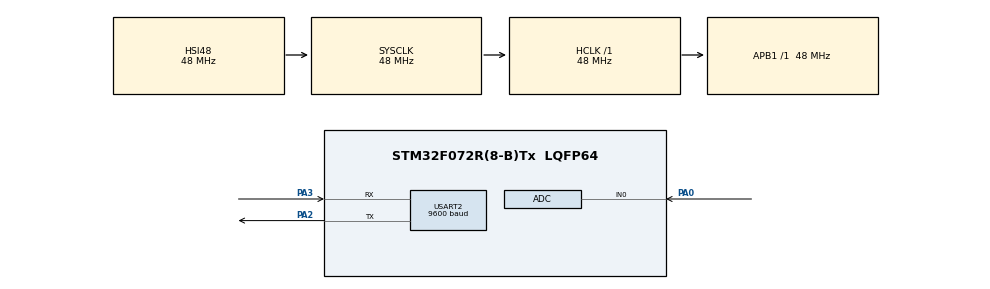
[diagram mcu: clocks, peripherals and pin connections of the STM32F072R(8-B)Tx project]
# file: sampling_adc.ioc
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ADC.ExternalTrigConv=ADC_EXTERNALTRIGCONV_T1_TRGO
Mcu.Family=STM32F0
Mcu.Name=STM32F072R(8-B)Tx
Mcu.Package=LQFP64
NVIC.ADC1_COMP_IRQn=true\:0\:0\:false\:false\:true\:true\:true
NVIC.TIM7_IRQn=true\:0\:0\:false\:false\:true\:true\:true
NVIC.USART2_IRQn=true\:0\:0\:false\:false\:true\:true\:true
PA0.Mode=IN0
PA0.Signal=ADC_IN0
PA2.Mode=Asynchronous
PA2.Signal=USART2_TX
PA3.Mode=Asynchronous
PA3.Signal=USART2_RX
ProjectManager.HeapSize=0x200
ProjectManager.StackSize=0x400
ProjectManager.TargetToolchain=MDK-ARM V5.27
RCC.AHBFreq_Value=48000000
RCC.APB1Freq_Value=48000000
RCC.APB1TimFreq_Value=48000000
RCC.HCLKFreq_Value=48000000
RCC.SYSCLKFreq_VALUE=48000000
RCC.SYSCLKSource=RCC_SYSCLKSOURCE_HSI48
TIM1.Period=48000
TIM1.TIM_MasterOutputTrigger=TIM_TRGO_ENABLE
TIM7.Period=48
TIM7.Prescaler=1
USART2.BaudRate=9600
USART2.VirtualMode-Asynchronous=VM_ASYNC
VP_ADC_Vref_Input.Mode=IN-Vrefint
VP_TIM1_VS_ClockSourceINT.Mode=Internal
VP_TIM7_VS_ClockSourceINT.Mode=Enable_Timer
board=custom

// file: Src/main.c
/* USER CODE BEGIN Header */
/**
  ******************************************************************************
  * @file           : main.c
  * @brief          : Main program body
  ******************************************************************************
  * @attention
  *
  * <h2><center>&copy; Copyright (c) 2019 STMicroelectronics.
  * All rights reserved.</center></h2>
  *
  * This software component is licensed by ST under BSD 3-Clause license,
  * the "License"; You may not use this file except in compliance with the
  * License. You may obtain a copy of the License at:
  *                        opensource.org/licenses/BSD-3-Clause
  *
  ******************************************************************************
  */
/* USER CODE END Header */

#include "main.h"

/* USER CODE BEGIN PTD */
#define size 100
int lenght_triggering=80;
int triggered=0;
int triggering=0;
int inizio=0;
int V_th=1000;
int values[size];
//float small_val[100]; //di questi verra fatto il valor medio, il quale verra inserito in values
int loops;
int i=0;//indice di values
int j=0;//indice di small_values
int ADC_CC=0; //adc conversion complete
uint32_t valore;
char msg[6];
int resto,m,m_1;
char * puntatore;
int lenght_da_trasmettere;
int vrefint_data;
int end=0;
int tmp1[100];
int tmp1_index,tmp2_index;
/* USER CODE END PTD */

ADC_HandleTypeDef hadc;

TIM_HandleTypeDef htim1;
TIM_HandleTypeDef htim7;

UART_HandleTypeDef huart2;

void SystemClock_Config(void);
static void MX_GPIO_Init(void);
static void MX_ADC_Init(void);
static void MX_USART2_UART_Init(void);
static void MX_TIM7_Init(void);
static void MX_TIM1_Init(void);

int main(void)
{
  /* USER CODE BEGIN 1 */
	int loops_2;
  /* USER CODE END 1 */

  /* MCU Configuration--------------------------------------------------------*/

  /* Reset of all peripherals, Initializes the Flash interface and the Systick. */
  HAL_Init();

  /* Configure the system clock */
  SystemClock_Config();

  /* Initialize all configured peripherals */
  MX_GPIO_Init();
  MX_ADC_Init();
  MX_USART2_UART_Init();
  MX_TIM7_Init();
  MX_TIM1_Init();
  /* USER CODE BEGIN 2 */
	ADC1->IER|=ADC_IER_ADRDYIE;
	ADC1->IER|=ADC_IER_EOCIE;

	//abilito e configuro l'adc
	//se fosse giа abilitato lo disabilito per fare la calibrazione
	if ((ADC1->CR & ADC_CR_ADEN) != 0)
	{
		ADC1->CR |= ADC_CR_ADDIS;
	}
	//aspetto che non sia piu enable
	while ((ADC1->CR & ADC_CR_ADEN) != 0){}
	//faccio la calibrazione
	ADC1->CR|=ADC_CR_ADCAL;
	//ed aspetto che abbia finito
	while((ADC1->CR & ADC_CR_ADCAL)==ADC_CR_ADCAL){}
	//se adrdy fosse 1 la metto a 0
	if ((ADC1->ISR & ADC_ISR_ADRDY) != 0)
	{
		ADC1->ISR |= ADC_ISR_ADRDY;
	}
	//abilito
	ADC1->CHSELR&=~ADC_CHSELR_CHSEL0;
	ADC1->CR|=ADC_CR_ADEN;
	ADC1->CR|=ADC_CR_ADSTART;
	TIM1->CR1|=TIM_CR1_CEN;
	//verra triggerato l'interrupt quando sarа pronto

	//adesso dovrebbe essere stato registrato il valore vrefint_data
	//aspetto 1 millisecondo

	//cambio il canale da cui leggere il dato nell'adc

	//faccio ripartire la lettura

	while(!ADC_CC){}
	//devo riordinare il buffer circolare

	if(inizio!=0){
		//riordino il buffer
		tmp1_index=inizio;
		while(tmp1_index!=lenght_triggering){
			tmp1[tmp1_index-inizio]=values[tmp1_index];
			tmp1_index++;
		}
		tmp2_index=0;
		while(tmp1_index!=lenght_triggering+inizio){
			tmp1[tmp1_index-inizio]=values[tmp2_index];
			tmp1_index++;
			tmp2_index++;
		}
		//copio in values
		tmp1_index=0;
		while(tmp1_index!=lenght_triggering){
			values[tmp1_index]=tmp1[tmp1_index];
			tmp1_index++;
		}
	}
	valore=*(uint16_t*)0x1FFFF7BA;
	m=valore;
	m_1=1000;
	msg[0]=(int)(m/m_1)+'0'; //m prima cifra
	resto=(m)%m_1;//resto
	msg[1]=(int)(resto*10/m_1)+'0';//m seconda cifra
	resto=(resto*10)%m_1;//resto
	msg[2]=(int)(resto*10/m_1)+'0';//m terza cifra
	resto=(resto*10)%m_1;
	msg[3]=(int)(resto*10/m_1)+'0';

	//trasmetto i dati con la usart2

	//reset del interrupt control register al bit trasmission completed
	USART2->ICR |= USART_ICR_TCCF;
	//abilito l'interrupt per la trasmissione
	USART2->CR1 |= USART_CR1_TCIE;
	//abilito l'interrupt per la ricezione
	USART2->CR1 |= USART_CR1_RXNEIE;
	//inizio a trasmettere il messaggio di benvenuto
	i=0;//indice msg
	j=-2;//indice values, aggiungo all'inizio valore e vrefint
	msg[4]=10;
	msg[5]=13;
	lenght_da_trasmettere=6;
	puntatore=msg;
	USART2->TDR=*puntatore;
  /* USER CODE END 2 */

  /* Infinite loop */
  while (1)
  {

  }
}

void SystemClock_Config(void)
{
  RCC_OscInitTypeDef RCC_OscInitStruct = {0};
  RCC_ClkInitTypeDef RCC_ClkInitStruct = {0};
  RCC_PeriphCLKInitTypeDef PeriphClkInit = {0};

  /** Initializes the CPU, AHB and APB busses clocks
  */
  RCC_OscInitStruct.OscillatorType = RCC_OSCILLATORTYPE_HSI14|RCC_OSCILLATORTYPE_HSI48;
  RCC_OscInitStruct.HSI48State = RCC_HSI48_ON;
  RCC_OscInitStruct.HSI14State = RCC_HSI14_ON;
  RCC_OscInitStruct.HSI14CalibrationValue = 16;
  RCC_OscInitStruct.PLL.PLLState = RCC_PLL_NONE;
  if (HAL_RCC_OscConfig(&RCC_OscInitStruct) != HAL_OK)
  {
    Error_Handler();
  }
  /** Initializes the CPU, AHB and APB busses clocks
  */
  RCC_ClkInitStruct.ClockType = RCC_CLOCKTYPE_HCLK|RCC_CLOCKTYPE_SYSCLK
                              |RCC_CLOCKTYPE_PCLK1;
  RCC_ClkInitStruct.SYSCLKSource = RCC_SYSCLKSOURCE_HSI48;
  RCC_ClkInitStruct.AHBCLKDivider = RCC_SYSCLK_DIV1;
  RCC_ClkInitStruct.APB1CLKDivider = RCC_HCLK_DIV1;

  if (HAL_RCC_ClockConfig(&RCC_ClkInitStruct, FLASH_LATENCY_1) != HAL_OK)
  {
    Error_Handler();
  }
  PeriphClkInit.PeriphClockSelection = RCC_PERIPHCLK_USART2;
  PeriphClkInit.Usart2ClockSelection = RCC_USART2CLKSOURCE_PCLK1;
  if (HAL_RCCEx_PeriphCLKConfig(&PeriphClkInit) != HAL_OK)
  {
    Error_Handler();
  }
}

static void MX_ADC_Init(void)
{

  ADC_ChannelConfTypeDef sConfig = {0};

  /** Configure the global features of the ADC (Clock, Resolution, Data Alignment and number of conversion)
  */
  hadc.Instance = ADC1;
  hadc.Init.ClockPrescaler = ADC_CLOCK_ASYNC_DIV1;
  hadc.Init.Resolution = ADC_RESOLUTION_12B;
  hadc.Init.DataAlign = ADC_DATAALIGN_RIGHT;
  hadc.Init.ScanConvMode = ADC_SCAN_DIRECTION_FORWARD;
  hadc.Init.EOCSelection = ADC_EOC_SINGLE_CONV;
  hadc.Init.LowPowerAutoWait = DISABLE;
  hadc.Init.LowPowerAutoPowerOff = DISABLE;
  hadc.Init.ContinuousConvMode = DISABLE;
  hadc.Init.DiscontinuousConvMode = DISABLE;
  hadc.Init.ExternalTrigConv = ADC_EXTERNALTRIGCONV_T1_TRGO;
  hadc.Init.ExternalTrigConvEdge = ADC_EXTERNALTRIGCONVEDGE_RISING;
  hadc.Init.DMAContinuousRequests = DISABLE;
  hadc.Init.Overrun = ADC_OVR_DATA_PRESERVED;
  if (HAL_ADC_Init(&hadc) != HAL_OK)
  {
    Error_Handler();
  }
  /** Configure for the selected ADC regular channel to be converted.
  */
  sConfig.Channel = ADC_CHANNEL_0;
  sConfig.Rank = ADC_RANK_CHANNEL_NUMBER;
  sConfig.SamplingTime = ADC_SAMPLETIME_1CYCLE_5;
  if (HAL_ADC_ConfigChannel(&hadc, &sConfig) != HAL_OK)
  {
    Error_Handler();
  }
  /** Configure for the selected ADC regular channel to be converted.
  */
  sConfig.Channel = ADC_CHANNEL_VREFINT;
  if (HAL_ADC_ConfigChannel(&hadc, &sConfig) != HAL_OK)
  {
    Error_Handler();
  }

}

static void MX_TIM1_Init(void)
{

  TIM_ClockConfigTypeDef sClockSourceConfig = {0};
  TIM_MasterConfigTypeDef sMasterConfig = {0};

  htim1.Instance = TIM1;
  htim1.Init.Prescaler = 0;
  htim1.Init.CounterMode = TIM_COUNTERMODE_UP;
  htim1.Init.Period = 48000;
  htim1.Init.ClockDivision = TIM_CLOCKDIVISION_DIV1;
  htim1.Init.RepetitionCounter = 0;
  htim1.Init.AutoReloadPreload = TIM_AUTORELOAD_PRELOAD_DISABLE;
  if (HAL_TIM_Base_Init(&htim1) != HAL_OK)
  {
    Error_Handler();
  }
  sClockSourceConfig.ClockSource = TIM_CLOCKSOURCE_INTERNAL;
  if (HAL_TIM_ConfigClockSource(&htim1, &sClockSourceConfig) != HAL_OK)
  {
    Error_Handler();
  }
  sMasterConfig.MasterOutputTrigger = TIM_TRGO_ENABLE;
  sMasterConfig.MasterSlaveMode = TIM_MASTERSLAVEMODE_DISABLE;
  if (HAL_TIMEx_MasterConfigSynchronization(&htim1, &sMasterConfig) != HAL_OK)
  {
    Error_Handler();
  }

}

static void MX_TIM7_Init(void)
{

  TIM_MasterConfigTypeDef sMasterConfig = {0};

  htim7.Instance = TIM7;
  htim7.Init.Prescaler = 1;
  htim7.Init.CounterMode = TIM_COUNTERMODE_UP;
  htim7.Init.Period = 48;
  htim7.Init.AutoReloadPreload = TIM_AUTORELOAD_PRELOAD_DISABLE;
  if (HAL_TIM_Base_Init(&htim7) != HAL_OK)
  {
    Error_Handler();
  }
  sMasterConfig.MasterOutputTrigger = TIM_TRGO_RESET;
  sMasterConfig.MasterSlaveMode = TIM_MASTERSLAVEMODE_DISABLE;
  if (HAL_TIMEx_MasterConfigSynchronization(&htim7, &sMasterConfig) != HAL_OK)
  {
    Error_Handler();
  }

}

static void MX_USART2_UART_Init(void)
{

  huart2.Instance = USART2;
  huart2.Init.BaudRate = 9600;
  huart2.Init.WordLength = UART_WORDLENGTH_8B;
  huart2.Init.StopBits = UART_STOPBITS_1;
  huart2.Init.Parity = UART_PARITY_NONE;
  huart2.Init.Mode = UART_MODE_TX_RX;
  huart2.Init.HwFlowCtl = UART_HWCONTROL_NONE;
  huart2.Init.OverSampling = UART_OVERSAMPLING_16;
  huart2.Init.OneBitSampling = UART_ONE_BIT_SAMPLE_DISABLE;
  huart2.AdvancedInit.AdvFeatureInit = UART_ADVFEATURE_NO_INIT;
  if (HAL_UART_Init(&huart2) != HAL_OK)
  {
    Error_Handler();
  }

}

static void MX_GPIO_Init(void)
{

  /* GPIO Ports Clock Enable */
  __HAL_RCC_GPIOA_CLK_ENABLE();

}

void Error_Handler(void)
{
}

/************************ (C) COPYRIGHT STMicroelectronics *****END OF FILE****/
